# AC33Mx384A register map
Vendor: ABOV Semiconductor Co., Ltd.; File version: 0.1
CPU: CM3 r1p0, little endian, no MPU, no FPU, 3 interrupt priority bits
Registers are 32-bit, read-write, reset 0x0 unless marked. A register's access mark holds for its fields unless they carry their own. Offsets are from the block's base; [hi:lo] are bit positions; {n}, {i} and the like mark numbered series; 'fields as' and 'values as' point back to an identical list.

## SCU — SYSTEM CONTROL UNIT
Base 0x40000000
0x00 CIDR ro reset 0xAC330384 — Chip ID Register
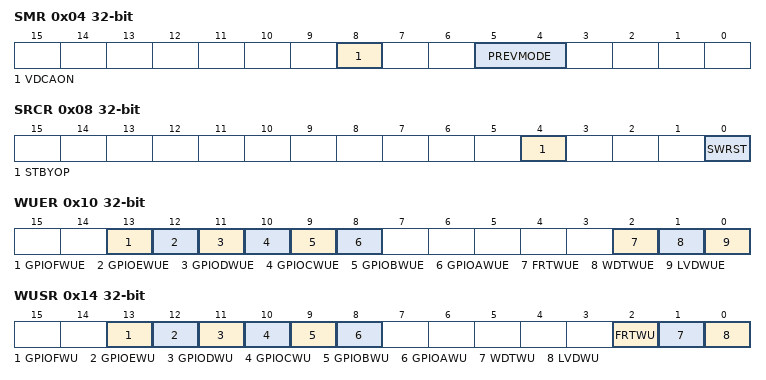
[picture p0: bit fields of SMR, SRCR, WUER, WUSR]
0x04 SMR — System Mode Register
  [8] VDCAON, [5:4] PREVMODE
0x08 SRCR — System Reset Control Register
  [4] STBYOP — STBOP pin output polarity select bit
  [0] SWRST — Internal soft reset activation
0x0C CIDR2 ro — Chip Revision ID Register
0x10 WUER — Wakeup Source Enable Register
  [13] GPIOFWUE, [12] GPIOEWUE, [11] GPIODWUE, [10] GPIOCWUE, [9] GPIOBWUE, [8] GPIOAWUE, [2] FRTWUE, [1] WDTWUE, [0] LVDWUE
0x14 WUSR — Wakeup Source Status Register
  [13] GPIOFWU, [12] GPIOEWU, [11] GPIODWU, [10] GPIOCWU, [9] GPIOBWU, [8] GPIOAWU, [2] FRTWU, [1] WDTWU, [0] LVDWU
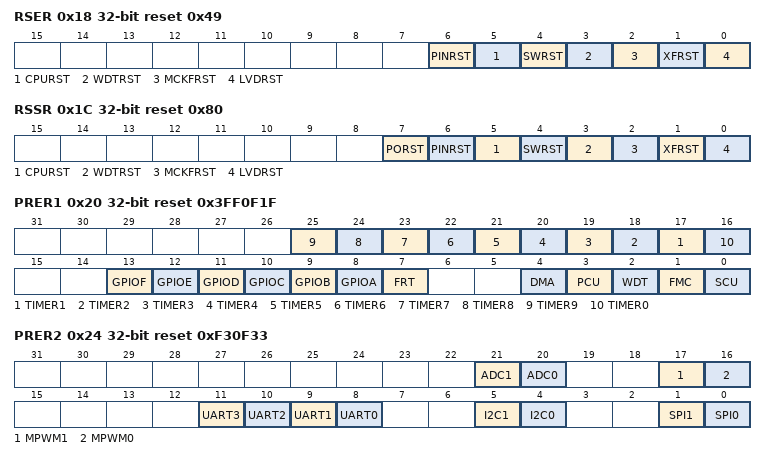
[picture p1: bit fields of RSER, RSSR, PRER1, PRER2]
0x18 RSER reset 0x49 — Reset Source Enable Register
  [6] PINRST — external pin reset enable
  [5] CPURST — CPU request reset enable
  [4] SWRST — software reset enable
  [3] WDTRST — watch dog reset enable
  [2] MCKFRST — MCLK failed reset enable
  [1] XFRST — external OSC clock failed enable
  [0] LVDRST — LVD reset enable
0x1C RSSR reset 0x80 — Reset Source Status Register
  [7] PORST — power on reset status
  [6] PINRST — extenral pin reset status
  [5] CPURST — cpu request reset status
  [4] SWRST — software reset status
  [3] WDTRST — watchdog timer reset status
  [2] MCKFRST — MCLK failed reset status
  [1] XFRST — clock failed reset status
  [0] LVDRST — lvd reset status
0x20 PRER1 reset 0x3FF0F1F — Peripheral Reset Enable Register 1
  [n+16] TIMER{n} (n=1..9) — TIMER{n} Reset
  [16] TIMER0 — TIMER0 reset
  [13] GPIOF — GPIOF Reset
  [12] GPIOE — GPIOE Reset
  [11] GPIOD — GPIOD Reset
  [10] GPIOC — GPIOC Reset
  [9] GPIOB — GPIOB Reset
  [8] GPIOA — GPIOA Reset
  [7] FRT — FRT Reset
  [4] DMA — DMA Reset
  [3] PCU — Port controll Reset
  [2] WDT — Watch Dog Timer Reset
  [1] FMC — Flash Memory controll Reset
  [0] SCU — Power Management Unit Reset
0x24 PRER2 reset 0xF30F33 — Peripheral Reset Enable Register 2
  [21] ADC1 — ADC1 Reset
  [20] ADC0 — ADC0 Reset
  [17] MPWM1 — MPWM1 Reset
  [16] MPWM0 — MPWM0 Reset
  [11] UART3
  [10] UART2
  [9] UART1
  [8] UART0 — UART0 Reset
  [5] I2C1 — I2C1 Reset
  [4] I2C0 — I2C0 Reset
  [1] SPI1 — SPI1 Reset
  [0] SPI0 — SPI0 Reset
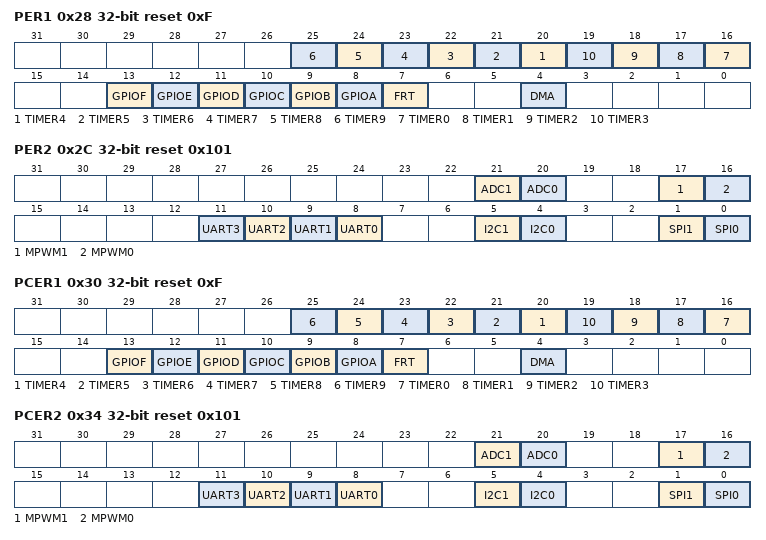
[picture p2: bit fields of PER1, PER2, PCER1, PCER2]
0x28 PER1 reset 0xF — Peripheral Enable Register 1
  [n+16] TIMER{n} (n=4..9) — TIMER{n} Enable
  [n+16] TIMER{n} (n=0..3)
  [13] GPIOF — GPIOD
  [12] GPIOE
  [11] GPIOD
  [10] GPIOC
  [9] GPIOB
  [8] GPIOA
  [7] FRT — FRT Function Enable
  [4] DMA — DMA Function Enable
0x2C PER2 reset 0x101 — Peripheral Enable Register 2
  [21] ADC1
  [20] ADC0
  [17] MPWM1 — MPWM1 Enable
  [16] MPWM0 — MPWM0 Enable
  [n+8] UART{n} (n=0..3) — UART{n} Enable
  [5] I2C1 — I2C1 Enable
  [4] I2C0 — I2C0 Enable
  [1] SPI1 — SPI1 Enable
  [0] SPI0 — SPI0 Enable
0x30 PCER1 reset 0xF — Peripheral Clock Enable Register 1
  [n+16] TIMER{n} (n=4..9) — TIMER{n} Enable
  [n+16] TIMER{n} (n=0..3)
  [13] GPIOF
  [12] GPIOE
  [11] GPIOD
  [10] GPIOC
  [9] GPIOB
  [8] GPIOA
  [7] FRT
  [4] DMA — DMA Function Enable
0x34 PCER2 reset 0x101 — Peripheral Clock Enable Register 2
  fields as PER2
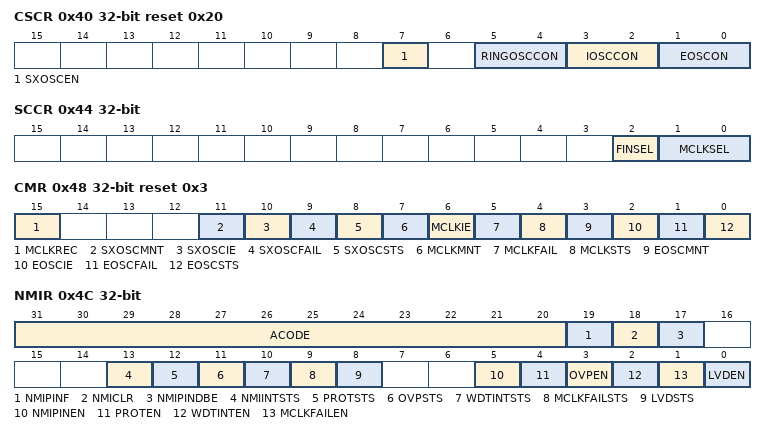
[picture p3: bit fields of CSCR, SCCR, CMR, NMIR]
0x40 CSCR reset 0x20 — Clock Source Control Register
  [7] SXOSCEN — Sub Oscillator Enable
  [5:4] RINGOSCCON — Internal ring OSC control
  [3:2] IOSCCON — Internal Oscillator control
  [1:0] EOSCON — External crystal OSC control
0x44 SCCR — System Clock Control Register
  [2] FINSEL — PLL Input source FIN Select
  [1:0] MCLKSEL — System clock select
0x48 CMR reset 0x3 — Clock Monitoring Register
  [15] MCLKREC ro — MCLK failed auto recovery
  [11] SXOSCMNT — Sub Oscillator monitoring enable
  [10] SXOSCIE — Sub Oscillator fail interrupt enable
  [9] SXOSCFAIL — Sub Oscillator fail interrupt flag
  [8] SXOSCSTS — Sub Oscillator clock status
  [7] MCLKMNT — MCLK monitor enable
  [6] MCLKIE — MCLK fail Interrupt enable
  [5] MCLKFAIL — MCLK Failed flag
  [4] MCLKSTS — MCLK clock status
  [3] EOSCMNT — Externaler OSC monitor enable
  [2] EOSCIE — external OSC failed interrupt enable
  [1] EOSCFAIL — external OSC failed flag
  [0] EOSCSTS — external OSC status
0x4C NMIR (reset mask 0xFFFF) — NMI Control Register
  [31:20] ACODE — 0xA32 to write
  [19] NMIPINF
  [18] NMICLR
  [17] NMIPINDBE
  [13] NMIINTSTS
  [12] PROTSTS
  [11] OVPSTS
  [10] WDTINTSTS
  [9] MCLKFAILSTS
  [8] LVDSTS
  [5] NMIPINEN
  [4] PROTEN
  [3] OVPEN
  [2] WDTINTEN
  [1] MCLKFAILEN
  [0] LVDEN
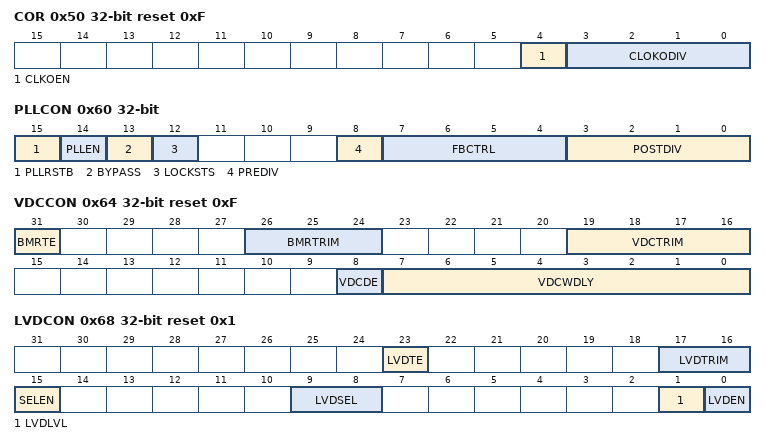
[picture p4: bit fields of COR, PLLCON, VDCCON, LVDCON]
0x50 COR reset 0xF — Clock Output Register
  [4] CLKOEN — clock output enable
  [3:0] CLOKODIV — clock output divider value
0x60 PLLCON — PLL Control Register
  [15] PLLRSTB — PLL reset
  [14] PLLEN — PLL Enable
  [13] BYPASS — FIN Bypass to FOUT
  [12] LOCKSTS ro — PLL Lock state
  [8] PREDIV — FIN pre divider
  [7:4] FBCTRL — Feedback control
  [3:0] POSTDIV — post divider
0x64 VDCCON reset 0xF — VDC Control Register
  [31] BMRTE wo
  [26:24] BMRTRIM
  [19:16] VDCTRIM
  [8] VDCDE wo
  [7:0] VDCWDLY — VDC warm up delay count
0x68 LVDCON reset 0x1 — LVD Control Register
  [23] LVDTE, [17:16] LVDTRIM, [15] SELEN, [9:8] LVDSEL, [1] LVDLVL, [0] LVDEN
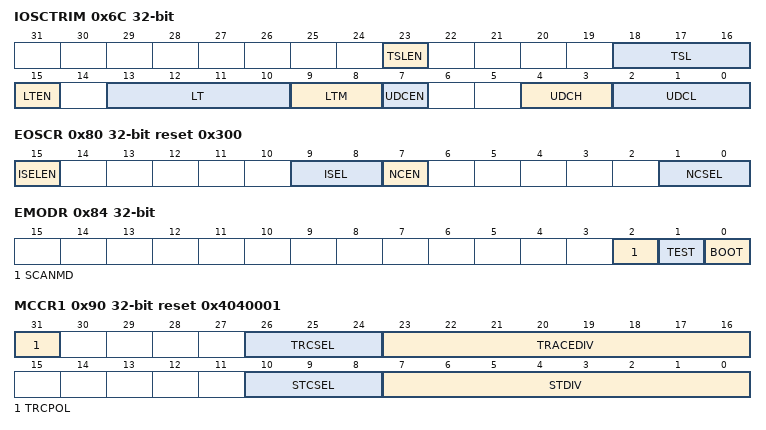
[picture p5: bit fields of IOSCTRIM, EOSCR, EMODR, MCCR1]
0x6C IOSCTRIM — Internal OSC Trim Registe
  [23] TSLEN wo — TSL trim value write enable
  [18:16] TSL — TSL trim value
  [15] LTEN wo — LTM_LT value write enable
  [13:10] LT — Internal oscillator LT trim value
  [9:8] LTM — Internal oscillator LT trim value
  [7] UDCEN wo — UDCH/UDCL value write enable
  [4:3] UDCH — Internal oscillator UDC trim value
  [2:0] UDCL — Internal oscillator UDC trim value
0x80 EOSCR reset 0x300 — External Oscillator Control Register
  [15] ISELEN wo — write enable for bit field ISEL
  [9:8] ISEL — select current
  [7] NCEN wo — Write enable of bit field NCSEL
  [1:0] NCSEL — Select noise cancel delay
0x84 EMODR — External Mode Status Register
  [2] SCANMD — scan mode pin level
  [1] TEST — TEST PIN level
  [0] BOOT — boot pin level
0x90 MCCR1 reset 0x4040001 — Miscellaneous Clock Control Register 1
  [31] TRCPOL wo
  [26:24] TRCSEL — trace clock source sel
  [23:16] TRACEDIV
  [10:8] STCSEL — systick clock source sel
  [7:0] STDIV — systick divider
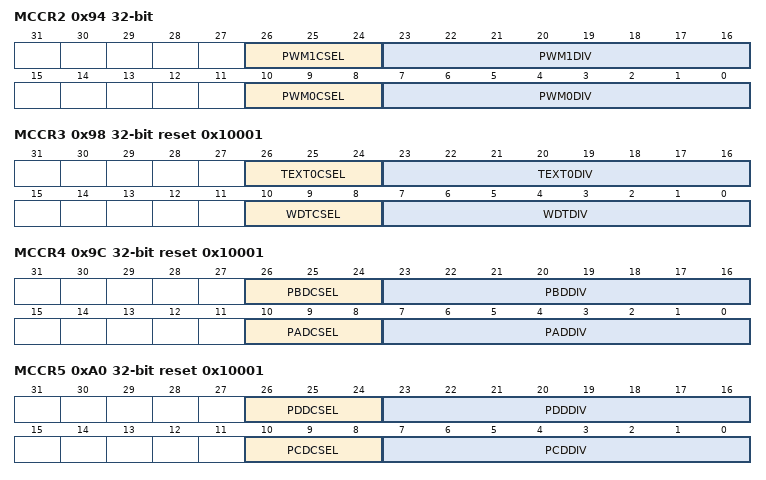
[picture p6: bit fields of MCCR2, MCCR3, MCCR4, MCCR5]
0x94 MCCR2 — Miscellaneous Clock Control Register 2
  [26:24] PWM1CSEL — pwm1 clock sel
  [23:16] PWM1DIV — PWM1 divider
  [10:8] PWM0CSEL — pwm0 clock sel
  [7:0] PWM0DIV — PWM0 divider
0x98 MCCR3 reset 0x10001 — Miscellaneous Clock Control Register 3
  [26:24] TEXT0CSEL — text0 clock sel
  [23:16] TEXT0DIV — text0 divider
  [10:8] WDTCSEL — WDT clock sel
  [7:0] WDTDIV — WDT divider
0x9C MCCR4 reset 0x10001 — Miscellaneous Clock Control Register 4
  [26:24] PBDCSEL — debouce clock for port B source clock sel
  [23:16] PBDDIV — PORT B debounce divider
  [10:8] PADCSEL — debouce clock for port A source clock sel
  [7:0] PADDIV — PORT A debounce divider
0xA0 MCCR5 reset 0x10001 — Miscellaneous Clock Control Register 5
  [26:24] PDDCSEL — debouce clock for port D source clock sel
  [23:16] PDDDIV — PORT D debounce divider
  [10:8] PCDCSEL — debouce clock for port C source clock sel
  [7:0] PCDDIV — PORT C debounce divider
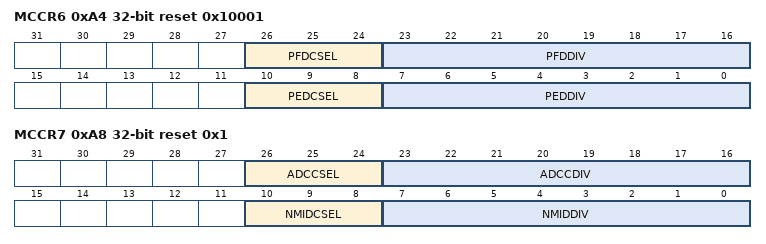
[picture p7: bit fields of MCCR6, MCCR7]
0xA4 MCCR6 reset 0x10001 — Miscellaneous Clock Control Register 6
  [26:24] PFDCSEL — debouce clock for port F source clock sel
  [23:16] PFDDIV — PORT F debounce divider
  [10:8] PEDCSEL — debouce clock for port E source clock sel
  [7:0] PEDDIV — PORT E debounce divider
0xA8 MCCR7 reset 0x1 — Miscellaneous Clock Control Register 7
  [26:24] ADCCSEL — ADC clock source select bit
  [23:16] ADCCDIV — ADC Clock N divider
  [10:8] NMIDCSEL — Debounce Clock for NMI source select bit
  [7:0] NMIDDIV — NMI Debounce Clock N divider
